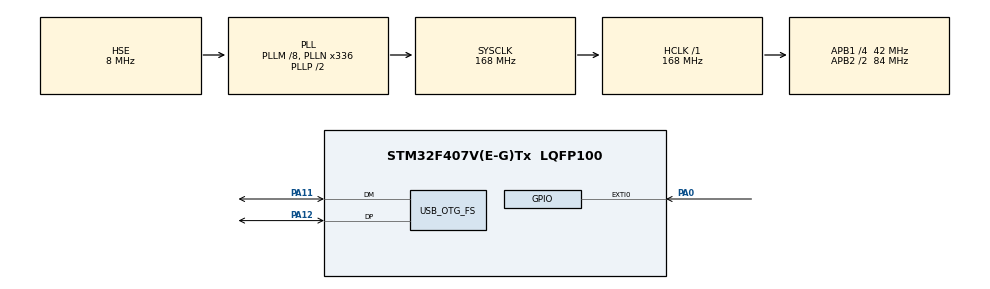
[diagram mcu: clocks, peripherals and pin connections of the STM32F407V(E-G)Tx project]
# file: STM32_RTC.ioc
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Mcu.Family=STM32F4
Mcu.Name=STM32F407V(E-G)Tx
Mcu.Package=LQFP100
NVIC.EXTI0_IRQn=true\:0\:0\:false\:false\:true\:true\:true\:true
NVIC.OTG_FS_IRQn=true\:0\:0\:false\:false\:true\:true\:true\:true
NVIC.PriorityGroup=NVIC_PRIORITYGROUP_0
PA0-WKUP.Signal=GPXTI0
PA11.Mode=Device_Only
PA11.Signal=USB_OTG_FS_DM
PA12.Mode=Device_Only
PA12.Signal=USB_OTG_FS_DP
PC14-OSC32_IN.Mode=LSE-External-Oscillator
PC14-OSC32_IN.Signal=RCC_OSC32_IN
PC15-OSC32_OUT.Mode=LSE-External-Oscillator
PC15-OSC32_OUT.Signal=RCC_OSC32_OUT
PH0-OSC_IN.Mode=HSE-External-Oscillator
PH0-OSC_IN.Signal=RCC_OSC_IN
PH1-OSC_OUT.Mode=HSE-External-Oscillator
PH1-OSC_OUT.Signal=RCC_OSC_OUT
ProjectManager.HeapSize=0x200
ProjectManager.StackSize=0x400
ProjectManager.TargetToolchain=STM32CubeIDE
RCC.48MHZClocksFreq_Value=48000000
RCC.AHBFreq_Value=168000000
RCC.APB1CLKDivider=RCC_HCLK_DIV4
RCC.APB1Freq_Value=42000000
RCC.APB1TimFreq_Value=84000000
RCC.APB2CLKDivider=RCC_HCLK_DIV2
RCC.APB2Freq_Value=84000000
RCC.APB2TimFreq_Value=168000000
RCC.CortexFreq_Value=168000000
RCC.HCLKFreq_Value=168000000
RCC.HSE_VALUE=8000000
RCC.HSI_VALUE=16000000
RCC.PLLM=8
RCC.PLLN=336
RCC.PLLQ=7
RCC.PLLSourceVirtual=RCC_PLLSOURCE_HSE
RCC.SYSCLKFreq_VALUE=168000000
RCC.SYSCLKSource=RCC_SYSCLKSOURCE_PLLCLK
RCC.VCOOutputFreq_Value=336000000
USB_DEVICE.CLASS_NAME_FS=CDC
USB_DEVICE.VirtualMode-CDC_FS=Cdc
USB_DEVICE.VirtualModeFS=Cdc_FS
USB_OTG_FS.VirtualMode=Device_Only
VP_RTC_VS_RTC_Activate.Mode=RTC_Enabled
VP_RTC_VS_RTC_Calendar.Mode=RTC_Calendar
VP_USB_DEVICE_VS_USB_DEVICE_CDC_FS.Mode=CDC_FS
board=STM32F407G-DISC1

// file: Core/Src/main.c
/* USER CODE BEGIN Header */
/**
  ******************************************************************************
  * @file           : main.c
  * @brief          : Main program body
  ******************************************************************************
  * @attention
  *
  * Copyright (c) 2024 STMicroelectronics.
  * All rights reserved.
  *
  * This software is licensed under terms that can be found in the LICENSE file
  * in the root directory of this software component.
  * If no LICENSE file comes with this software, it is provided AS-IS.
  *
  ******************************************************************************
  */
/* USER CODE END Header */
#include "main.h"
#include "usb_device.h"

/* USER CODE BEGIN Includes */
#include"Message.h"

/* USER CODE END Includes */

RTC_HandleTypeDef hrtc;

void SystemClock_Config(void);
static void MX_GPIO_Init(void);
static void MX_RTC_Init(void);

/* USER CODE BEGIN 0 */

RTC_TimeTypeDef Int_RTC_Time;
RTC_DateTypeDef Int_RTC_Date;
char dizi[64];
int successfulMessageCount = 0; // Hatasiz mesaj sayaci
int errorMessageCount = 0;     // Hatali mesaj sayaci
char buffer[64];
//£FFFF010901170C3A1B% ->Write
//£FFFF00% ->Read

/* USER CODE END 0 */

int main(void)
{

  /* MCU Configuration--------------------------------------------------------*/

  /* Reset of all peripherals, Initializes the Flash interface and the Systick. */
  HAL_Init();

  /* Configure the system clock */
  SystemClock_Config();

  /* Initialize all configured peripherals */
  MX_GPIO_Init();
  MX_RTC_Init();
  MX_USB_DEVICE_Init();

  /* Infinite loop */
  while (1)
  {

    /* USER CODE BEGIN 3 */
	  HAL_RTC_GetTime(&hrtc, &Int_RTC_Time, RTC_FORMAT_BIN);
	  HAL_RTC_GetDate(&hrtc, &Int_RTC_Date, RTC_FORMAT_BIN);
	  HAL_Delay(100);
  }
  /* USER CODE END 3 */
}

void SystemClock_Config(void)
{
  RCC_OscInitTypeDef RCC_OscInitStruct = {0};
  RCC_ClkInitTypeDef RCC_ClkInitStruct = {0};

  /** Configure the main internal regulator output voltage
  */
  __HAL_RCC_PWR_CLK_ENABLE();
  __HAL_PWR_VOLTAGESCALING_CONFIG(PWR_REGULATOR_VOLTAGE_SCALE1);

  /** Initializes the RCC Oscillators according to the specified parameters
  * in the RCC_OscInitTypeDef structure.
  */
  RCC_OscInitStruct.OscillatorType = RCC_OSCILLATORTYPE_LSI|RCC_OSCILLATORTYPE_HSE;
  RCC_OscInitStruct.HSEState = RCC_HSE_ON;
  RCC_OscInitStruct.LSIState = RCC_LSI_ON;
  RCC_OscInitStruct.PLL.PLLState = RCC_PLL_ON;
  RCC_OscInitStruct.PLL.PLLSource = RCC_PLLSOURCE_HSE;
  RCC_OscInitStruct.PLL.PLLM = 8;
  RCC_OscInitStruct.PLL.PLLN = 336;
  RCC_OscInitStruct.PLL.PLLP = RCC_PLLP_DIV2;
  RCC_OscInitStruct.PLL.PLLQ = 7;
  if (HAL_RCC_OscConfig(&RCC_OscInitStruct) != HAL_OK)
  {
    Error_Handler();
  }

  /** Initializes the CPU, AHB and APB buses clocks
  */
  RCC_ClkInitStruct.ClockType = RCC_CLOCKTYPE_HCLK|RCC_CLOCKTYPE_SYSCLK
                              |RCC_CLOCKTYPE_PCLK1|RCC_CLOCKTYPE_PCLK2;
  RCC_ClkInitStruct.SYSCLKSource = RCC_SYSCLKSOURCE_PLLCLK;
  RCC_ClkInitStruct.AHBCLKDivider = RCC_SYSCLK_DIV1;
  RCC_ClkInitStruct.APB1CLKDivider = RCC_HCLK_DIV4;
  RCC_ClkInitStruct.APB2CLKDivider = RCC_HCLK_DIV2;

  if (HAL_RCC_ClockConfig(&RCC_ClkInitStruct, FLASH_LATENCY_5) != HAL_OK)
  {
    Error_Handler();
  }
}

static void MX_RTC_Init(void)
{

  RTC_TimeTypeDef sTime = {0};
  RTC_DateTypeDef sDate = {0};

  /** Initialize RTC Only
  */
  hrtc.Instance = RTC;
  hrtc.Init.HourFormat = RTC_HOURFORMAT_24;
  hrtc.Init.AsynchPrediv = 127;
  hrtc.Init.SynchPrediv = 255;
  hrtc.Init.OutPut = RTC_OUTPUT_DISABLE;
  hrtc.Init.OutPutPolarity = RTC_OUTPUT_POLARITY_HIGH;
  hrtc.Init.OutPutType = RTC_OUTPUT_TYPE_OPENDRAIN;
  if (HAL_RTC_Init(&hrtc) != HAL_OK)
  {
    Error_Handler();
  }

  /** Initialize RTC and set the Time and Date
  */
  sTime.Hours = 0x0;
  sTime.Minutes = 0x0;
  sTime.Seconds = 0x0;
  sTime.DayLightSaving = RTC_DAYLIGHTSAVING_NONE;
  sTime.StoreOperation = RTC_STOREOPERATION_RESET;
  if (HAL_RTC_SetTime(&hrtc, &sTime, RTC_FORMAT_BCD) != HAL_OK)
  {
    Error_Handler();
  }
  sDate.WeekDay = RTC_WEEKDAY_MONDAY;
  sDate.Month = RTC_MONTH_JANUARY;
  sDate.Date = 0x1;
  sDate.Year = 0x0;

  if (HAL_RTC_SetDate(&hrtc, &sDate, RTC_FORMAT_BCD) != HAL_OK)
  {
    Error_Handler();
  }

}

static void MX_GPIO_Init(void)
{
  GPIO_InitTypeDef GPIO_InitStruct = {0};

  /* GPIO Ports Clock Enable */
  __HAL_RCC_GPIOC_CLK_ENABLE();
  __HAL_RCC_GPIOH_CLK_ENABLE();
  __HAL_RCC_GPIOA_CLK_ENABLE();

  /*Configure GPIO pin : PA0 */
  GPIO_InitStruct.Pin = GPIO_PIN_0;
  GPIO_InitStruct.Mode = GPIO_MODE_IT_RISING;
  GPIO_InitStruct.Pull = GPIO_NOPULL;
  HAL_GPIO_Init(GPIOA, &GPIO_InitStruct);

  /* EXTI interrupt init*/
  HAL_NVIC_SetPriority(EXTI0_IRQn, 0, 0);
  HAL_NVIC_EnableIRQ(EXTI0_IRQn);

}

/* USER CODE BEGIN 4 */
void HAL_GPIO_EXTI_Callback(uint16_t GPIO_Pin){
	Int_RTC_Time.Hours=10;
	Int_RTC_Time.Minutes=10;
	Int_RTC_Time.Seconds=10;
	HAL_RTC_SetTime(&hrtc, &Int_RTC_Time, RTC_FORMAT_BIN);
	Int_RTC_Date.WeekDay=RTC_WEEKDAY_SUNDAY;
	Int_RTC_Date.Month=RTC_MONTH_JANUARY;
	HAL_RTC_SetDate(&hrtc, &Int_RTC_Date, RTC_FORMAT_BIN);

}

/* USER CODE END 4 */

void Error_Handler(void)
{
  __disable_irq();
  while (1)
  {
  }
}
